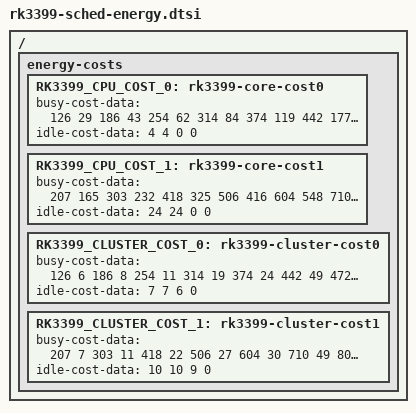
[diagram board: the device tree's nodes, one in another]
/*
 * Copyright (c) 2016 Fuzhou Rockchip Electronics Co., Ltd
 *
 * This file is dual-licensed: you can use it either under the terms
 * of the GPL or the X11 license, at your option. Note that this dual
 * licensing only applies to this file, and not this project as a
 * whole.
 *
 *  a) This library is free software; you can redistribute it and/or
 *     modify it under the terms of the GNU General Public License as
 *     published by the Free Software Foundation; either version 2 of the
 *     License, or (at your option) any later version.
 *
 *     This library is distributed in the hope that it will be useful,
 *     but WITHOUT ANY WARRANTY; without even the implied warranty of
 *     MERCHANTABILITY or FITNESS FOR A PARTICULAR PURPOSE.  See the
 *     GNU General Public License for more details.
 *
 * Or, alternatively,
 *
 *  b) Permission is hereby granted, free of charge, to any person
 *     obtaining a copy of this software and associated documentation
 *     files (the "Software"), to deal in the Software without
 *     restriction, including without limitation the rights to use,
 *     copy, modify, merge, publish, distribute, sublicense, and/or
 *     sell copies of the Software, and to permit persons to whom the
 *     Software is furnished to do so, subject to the following
 *     conditions:
 *
 *     The above copyright notice and this permission notice shall be
 *     included in all copies or substantial portions of the Software.
 *
 *     THE SOFTWARE IS PROVIDED "AS IS", WITHOUT WARRANTY OF ANY KIND,
 *     EXPRESS OR IMPLIED, INCLUDING BUT NOT LIMITED TO THE WARRANTIES
 *     OF MERCHANTABILITY, FITNESS FOR A PARTICULAR PURPOSE AND
 *     NONINFRINGEMENT. IN NO EVENT SHALL THE AUTHORS OR COPYRIGHT
 *     HOLDERS BE LIABLE FOR ANY CLAIM, DAMAGES OR OTHER LIABILITY,
 *     WHETHER IN AN ACTION OF CONTRACT, TORT OR OTHERWISE, ARISING
 *     FROM, OUT OF OR IN CONNECTION WITH THE SOFTWARE OR THE USE OR
 *     OTHER DEALINGS IN THE SOFTWARE.
 */

/ {
	energy-costs {
		RK3399_CPU_COST_0: rk3399-core-cost0 {
			busy-cost-data = <
				126    29	/*  408M */
				186    43	/*  600M */
				254    62	/*  816M */
				314    84	/* 1008M */
				374    119	/* 1200M */
				442    177	/* 1416M */
				472    215	/* 1512M */
			>;
			idle-cost-data = <
				4
				4
				0
				0
			>;
		};

		RK3399_CPU_COST_1: rk3399-core-cost1 {
			busy-cost-data = <
				207   165	/*  408MHz */
				303   232	/*  600MHz */
				418   325	/*  816MHz */
				506   416	/* 1008MHz */
				604   548	/* 1200MHz */
				710   759	/* 1416MHz */
				805   1012	/* 1608MHz */
				904   1385	/* 1800MHz */
				1024  1893	/* 2016MHz */
			>;
			idle-cost-data = <
				24
				24
				0
				0
			>;
		};

		RK3399_CLUSTER_COST_0: rk3399-cluster-cost0 {
			busy-cost-data = <
				126    6	/*  408M */
				186    8	/*  600M */
				254    11	/*  816M */
				314    19	/* 1008M */
				374    24	/* 1200M */
				442    49	/* 1416M */
				472    56	/* 1512M */
			>;
			idle-cost-data = <
				7
				7
				6
				0
			>;
		};

		RK3399_CLUSTER_COST_1: rk3399-cluster-cost1 {
			busy-cost-data = <
				207   7		/*  408MHz */
				303   11	/*  600MHz */
				418   22	/*  816MHz */
				506   27	/* 1008MHz */
				604   30	/* 1200MHz */
				710   49	/* 1416MHz */
				805   56	/* 1608MHz */
				904   63	/* 1800MHz */
				1024  78	/* 2016MHz */
			>;
			idle-cost-data = <
				10
				10
				9
				0
			>;
		};
	};
};
